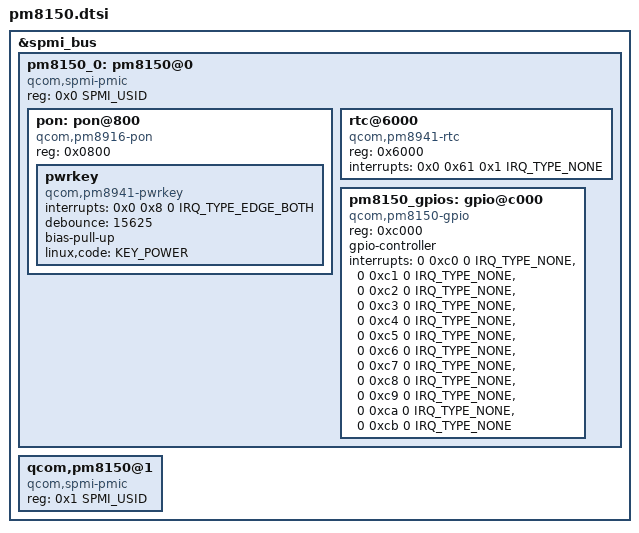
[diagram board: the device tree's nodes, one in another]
// SPDX-License-Identifier: BSD-3-Clause
// Copyright (c) 2017-2019, The Linux Foundation. All rights reserved.
// Copyright (c) 2019, Linaro Limited

#include <dt-bindings/input/input.h>
#include <dt-bindings/interrupt-controller/irq.h>
#include <dt-bindings/spmi/spmi.h>

&spmi_bus {
	pm8150_0: pm8150@0 {
		compatible = "qcom,spmi-pmic";
		reg = <0x0 SPMI_USID>;
		#address-cells = <1>;
		#size-cells = <0>;

		pon: pon@800 {
			compatible = "qcom,pm8916-pon";
			reg = <0x0800>;
			pwrkey {
				compatible = "qcom,pm8941-pwrkey";
				interrupts = <0x0 0x8 0 IRQ_TYPE_EDGE_BOTH>;
				debounce = <15625>;
				bias-pull-up;
				linux,code = <KEY_POWER>;
			};
		};

		rtc@6000 {
			compatible = "qcom,pm8941-rtc";
			reg = <0x6000>;
			reg-names = "rtc", "alarm";
			interrupts = <0x0 0x61 0x1 IRQ_TYPE_NONE>;
		};

		pm8150_gpios: gpio@c000 {
			compatible = "qcom,pm8150-gpio";
			reg = <0xc000>;
			gpio-controller;
			#gpio-cells = <2>;
			interrupts = <0 0xc0 0 IRQ_TYPE_NONE>,
				     <0 0xc1 0 IRQ_TYPE_NONE>,
				     <0 0xc2 0 IRQ_TYPE_NONE>,
				     <0 0xc3 0 IRQ_TYPE_NONE>,
				     <0 0xc4 0 IRQ_TYPE_NONE>,
				     <0 0xc5 0 IRQ_TYPE_NONE>,
				     <0 0xc6 0 IRQ_TYPE_NONE>,
				     <0 0xc7 0 IRQ_TYPE_NONE>,
				     <0 0xc8 0 IRQ_TYPE_NONE>,
				     <0 0xc9 0 IRQ_TYPE_NONE>,
				     <0 0xca 0 IRQ_TYPE_NONE>,
				     <0 0xcb 0 IRQ_TYPE_NONE>;
		};
	};

	qcom,pm8150@1 {
		compatible ="qcom,spmi-pmic";
		reg = <0x1 SPMI_USID>;
		#address-cells = <1>;
		#size-cells = <0>;
	};
};
